# STM32L0x1 register map
File version: 1.6
CPU: CM0+ r0p0, little endian, MPU, no FPU, 2 interrupt priority bits
Registers are 32-bit, read-write, reset 0x0 unless marked. A register's access mark holds for its fields unless they carry their own. Offsets are from the block's base; [hi:lo] are bit positions; {n}, {i} and the like mark numbered series.

## WWDG — System window watchdog
Base 0x40002C00
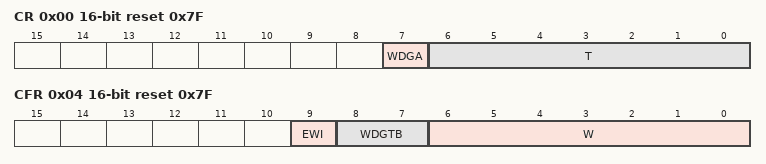
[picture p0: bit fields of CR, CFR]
0x00 CR 16-bit reset 0x7F — Control register
  [7] WDGA — Activation bit
    0=Disabled (Watchdog disabled); 1=Enabled (Watchdog enabled)
  [6:0] T — 7-bit counter (MSB to LSB)
0x04 CFR 16-bit reset 0x7F — Configuration register
  [9] EWI — Early wakeup interrupt
    on write: 1=Enable (interrupt occurs whenever the counter reaches the value 0x40)
  [8:7] WDGTB — Timer base
    0=Div1 (Counter clock (PCLK1 div 4096) div 1); 1=Div2 (Counter clock (PCLK1 div 4096) div 2); 2=Div4 (Counter clock (PCLK1 div 4096) div 4); 3=Div8 (Counter clock (PCLK1 div 4096) div 8)
  [6:0] W — 7-bit window value
0x08 SR 16-bit — Status register
  [0] EWIF write-0-clears — Early wakeup interrupt flag
    on read: 0=Finished (The EWI Interrupt Service Routine has been serviced); 1=Pending (The EWI Interrupt Service Routine has been triggered) | on write: 0=Finished (The EWI Interrupt Service Routine has been serviced)

## FW — Firewall
Base 0x40011C00
0x00 CSSA — Code segment start address
  [23:8] ADD — code segment start address
0x04 CSL — Code segment length
  [21:8] LENG — code segment length
0x08 NVDSSA — Non-volatile data segment start address
  [23:8] ADD
0x0C NVDSL — Non-volatile data segment length
  [21:8] LENG
0x10 VDSSA — Volatile data segment start address
  [15:6] ADD
0x14 VDSL — Volatile data segment length
  [15:6] LENG — Non-volatile data segment length
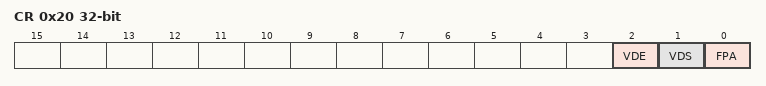
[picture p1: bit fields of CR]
0x20 CR — Configuration register
  [2] VDE — Volatile data execution
    on read: 0=NotExecutable (Volatile data segment cannot be executed if VDS = 0); 1=Executable (Volatile data segment is declared executable whatever VDS bit value) | on write: 0=Resets volatile data execution bit
  [1] VDS — Volatile data shared
    on read: 0=NotShared (Volatile data segment is not shared and cannot be hit by a non protected executable code when the Firewall is closed); 1=Shared (Volatile data segment is shared with non protected application code) | on write: 0=Resets volatile data shared bit
  [0] FPA — Firewall pre alarm
    on write: 0=PreArmReset (Any code executed outside the protected segment when the Firewall is opened will generate a system reset); 1=PreArmSet (Any code executed outside the protected segment will close the Firewall)

## EXTI — External interrupt/event controller
Base 0x40010400
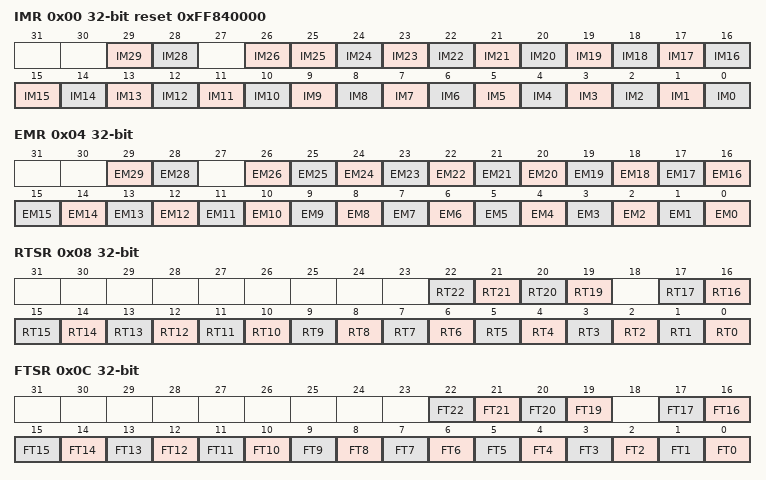
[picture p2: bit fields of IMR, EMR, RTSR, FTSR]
0x00 IMR reset 0xFF840000 — Interrupt mask register (EXTI_IMR)
  [all] fields
    0=Masked (Interrupt request line is masked); 1=Unmasked (Interrupt request line is unmasked)
  [29] IM29 — Interrupt Mask on line 27
  [28] IM28 — Interrupt Mask on line 27
  [26] IM26 — Interrupt Mask on line 27
  [n] IM{n} (n=0..25) — Interrupt Mask on line {n}
0x04 EMR — Event mask register (EXTI_EMR)
  [all] fields
    0=Masked (Event request line is masked); 1=Unmasked (Event request line is unmasked)
  [29] EM29 — Event Mask on line 29
  [28] EM28 — Event Mask on line 28
  [n] EM{n} (n=0..26) — Event Mask on line {n}
0x08 RTSR — Rising Trigger selection register (EXTI_RTSR)
  [all] fields
    0=Disabled (Rising edge trigger is disabled); 1=Enabled (Rising edge trigger is enabled)
  [n] RT{n} (n=19..22) — Rising trigger event configuration of line {n}
  [n] RT{n} (n=0..17) — Rising trigger event configuration of line {n}
0x0C FTSR — Falling Trigger selection register (EXTI_FTSR)
  [all] fields
    0=Disabled (Falling edge trigger is disabled); 1=Enabled (Falling edge trigger is enabled)
  [n] FT{n} (n=19..22) — Falling trigger event configuration of line {n}
  [n] FT{n} (n=0..17) — Falling trigger event configuration of line {n}
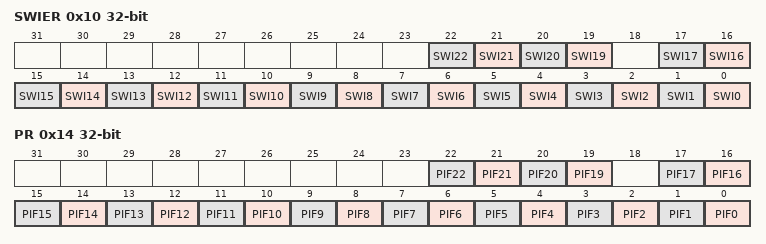
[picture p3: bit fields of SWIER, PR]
0x10 SWIER — Software interrupt event register (EXTI_SWIER)
  [all] fields
    on write: 1=Pend (Generates an interrupt request)
  [n] SWI{n} (n=19..22) — Software Interrupt on line {n}
  [n] SWI{n} (n=0..17) — Software Interrupt on line {n}
0x14 PR — Pending register (EXTI_PR)
  [all] fields
    on read: 0=NotPending (No trigger request occurred); 1=Pending (Selected trigger request occurred) | on write: 1=Clears pending bit
  [n] PIF{n} write-1-clears (n=19..22) — Pending bit {n}
  [n] PIF{n} write-1-clears (n=0..17) — Pending bit {n}
